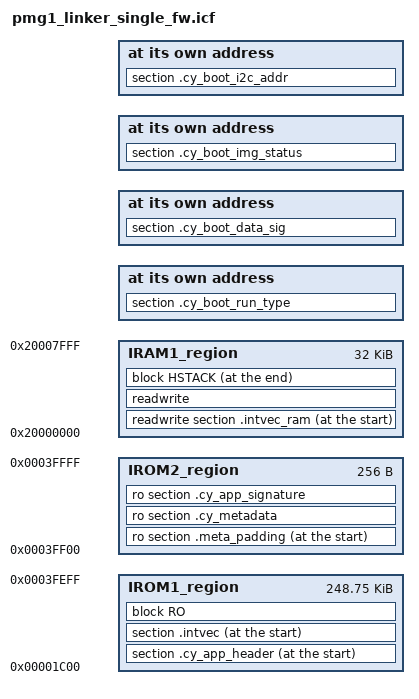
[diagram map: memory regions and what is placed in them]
/*******************************************************************************
* \file pmg1_linker_single_fw.icf
* \version 1.0.0
*
* Linker file for the IAR compiler.
*
* The main purpose of the linker script is to describe how the sections in the
* input files should be mapped into the output file, and to control the memory
* layout of the output file.
*
* \note The entry point is fixed and starts at 0x00000000. The valid application
* image should be placed there.
*
* \note The linker files included with the PDL template projects must be generic
* and handle all common use cases. Your project may not use every section
* defined in the linker files. In that case you may see warnings during the
* build process. In your project, you can simply comment out or remove the
* relevant code in the linker file.
*
********************************************************************************
* \copyright
* (c) (2024), Cypress Semiconductor Corporation (an Infineon company) or
* an affiliate of Cypress Semiconductor Corporation.
*
* SPDX-License-Identifier: Apache-2.0
*
* Licensed under the Apache License, Version 2.0 (the "License");
* you may not use this file except in compliance with the License.
* You may obtain a copy of the License at
*
*     http://www.apache.org/licenses/LICENSE-2.0
*
* Unless required by applicable law or agreed to in writing, software
* distributed under the License is distributed on an "AS IS" BASIS,
* WITHOUT WARRANTIES OR CONDITIONS OF ANY KIND, either express or implied.
* See the License for the specific language governing permissions and
* limitations under the License.
*******************************************************************************/

/*###ICF### Section handled by ICF editor, don't touch! ****/
/*-Editor annotation file-*/
/* IcfEditorFile="$TOOLKIT_DIR$\config\ide\IcfEditor\cortex_v1_4.xml" */
/*-Specials-*/
define symbol __ICFEDIT_intvec_start__ = 0x00000000;

/* The symbols below define the location and size of blocks of memory in the target.
 * Use these symbols to specify the memory regions available for allocation.
 */

/* The following symbols control RAM and flash memory allocation.
 * You can change the memory allocation by editing RAM and Flash symbols.
 */
/* RAM */
define symbol __ICFEDIT_region_IRAM1_start__         = 0x20000000;
define symbol __ICFEDIT_region_IRAM1_end__           = 0x20007FFF;
define symbol __ICFEDIT_region_IRAM2_start__         = 0x0;
define symbol __ICFEDIT_region_IRAM2_end__           = 0x0;
define symbol __ICFEDIT_region_IRAM3_start__         = 0x0;
define symbol __ICFEDIT_region_IRAM3_end__           = 0x0;
define symbol __ICFEDIT_region_ERAM1_start__         = 0x0;
define symbol __ICFEDIT_region_ERAM1_end__           = 0x0;
define symbol __ICFEDIT_region_ERAM2_start__         = 0x0;
define symbol __ICFEDIT_region_ERAM2_end__           = 0x0;
define symbol __ICFEDIT_region_ERAM3_start__         = 0x0;
define symbol __ICFEDIT_region_ERAM3_end__           = 0x0;

/* Flash */
define symbol __ICFEDIT_region_IROM_Boot_start__     = 0x00000000;
define symbol __ICFEDIT_region_IROM_Boot_end__       = 0x00001BFF;
define symbol __ICFEDIT_region_IROM_Fw_start__       = 0x00001C00;
define symbol __ICFEDIT_region_IROM_Fw_end__         = 0x0003FEFF;
define symbol __ICFEDIT_region_IROM_Fw_Meta_start__  = 0x0003FF00;
define symbol __ICFEDIT_region_IROM_Fw_Meta_end__    = 0x0003FFFF;
define symbol __ICFEDIT_region_EROM1_start__         = 0x0;
define symbol __ICFEDIT_region_EROM1_end__           = 0x0;
define symbol __ICFEDIT_region_EROM2_start__         = 0x0;
define symbol __ICFEDIT_region_EROM2_end__           = 0x0;
define symbol __ICFEDIT_region_EROM3_start__         = 0x0;
define symbol __ICFEDIT_region_EROM3_end__           = 0x0;

/*-Sizes-*/
if (!isdefinedsymbol(__STACK_SIZE)) {
define symbol __ICFEDIT_size_cstack__ = 0x0400;
} else {
define symbol __ICFEDIT_size_cstack__ = __STACK_SIZE;
}
define symbol __ICFEDIT_size_proc_stack__ = 0x0;

/* Defines the minimum heap size. The actual heap size will be expanded to the end of the stack region */
if (!isdefinedsymbol(__HEAP_SIZE)) {
define symbol __ICFEDIT_size_heap__ = 0x0080;
} else {
define symbol __ICFEDIT_size_heap__ = __HEAP_SIZE;
}
/**** End of ICF editor section. ###ICF###*/


define memory mem with size = 4G;
define symbol use_IROM1 = (__ICFEDIT_region_IROM_Fw_start__ != 0x0 || __ICFEDIT_region_IROM_Fw_end__ != 0x0);
define symbol use_IROM2 = (__ICFEDIT_region_IROM_Fw_Meta_start__ != 0x0 || __ICFEDIT_region_IROM_Fw_Meta_end__ != 0x0);
define symbol use_IRAM1 = (__ICFEDIT_region_IRAM1_start__ != 0x0 || __ICFEDIT_region_IRAM1_end__ != 0x0);

define region IROM1_region = mem:[from __ICFEDIT_region_IROM_Fw_start__ to __ICFEDIT_region_IROM_Fw_end__];
define region IROM2_region = mem:[from __ICFEDIT_region_IROM_Fw_Meta_start__ to __ICFEDIT_region_IROM_Fw_Meta_end__];
define region IRAM1_region = mem:[from __ICFEDIT_region_IRAM1_start__ to __ICFEDIT_region_IRAM1_end__];

define block CSTACK     with alignment = 8, size = __ICFEDIT_size_cstack__     { };
define block PROC_STACK with alignment = 8, size = __ICFEDIT_size_proc_stack__ { };
define block HEAP       with expanding size, alignment = 8, minimum size = __ICFEDIT_size_heap__ { };
define block HSTACK {block HEAP, block PROC_STACK, last block CSTACK};
define block RO     {readonly};

/*-Initializations-*/
initialize by copy { readwrite };
do not initialize  { section .noinit, section .intvec_ram };

/*-Placement-*/

/* Flash - Application Firmware section */
".cy_app_header" : place at start of IROM1_region  { section .cy_app_header };
place at start of                    IROM1_region  { section .intvec };
place at address mem : start(IROM1_region) + 0xC0  { section .customer_region };
place at address mem : start(IROM1_region) + 0xE0  { section .cy_base_version, section .cy_app_version, section .cy_dev_siliconid, section .cy_fw_reserved};
place in                             IROM1_region  { block RO };

/* Metadata section */
".meta_padding"     : place at start of  IROM2_region  {ro section .meta_padding };
".cy_metadata"      : place in           IROM2_region  {ro section .cy_metadata};
".cy_app_signature" : place in           IROM2_region  {ro section .cy_app_signature};

/* RAM */
place at start of IRAM1_region  { readwrite section .intvec_ram};
place at address mem: start(IRAM1_region) + 0xC0  { section .cy_boot_run_type};
place at address mem: start(IRAM1_region) + 0xC4  { section .cy_boot_data_sig};
place at address mem: start(IRAM1_region) + 0xC8  { section .cy_boot_img_status};
place at address mem: start(IRAM1_region) + 0xCC  { section .cy_boot_i2c_addr};
place in          IRAM1_region  { readwrite };
place at end   of IRAM1_region  { block HSTACK };

/* These sections are used for additional metadata (silicon revision, Silicon/JTAG ID, etc.) storage. */
".cyflashprotect" : place at address mem : 0x90400000 { readonly section .cyflashprotect };
".cymeta"         : place at address mem : 0x90500000 { readonly section .cymeta };
".cychipprotect"  : place at address mem : 0x90600000 { readonly section .cychipprotect };


keep {  section .cy_app_header,
        section .vectors,
        section .customer_region,
        section .cy_base_version,
        section .cy_app_version,
        section .cy_dev_siliconid,
        section .cy_fw_reserved,
        section .cy_boot_run_type,
        section .cy_boot_data_sig,
        section .cy_boot_img_status,
        section .cy_boot_i2c_addr,
        section .meta_padding,
        section .cy_metadata,
        section .cy_app_signature,
        section .cyflashprotect,
        section .cymeta,
        section .cychipprotect,
         };


/* The following symbols used by the cymcuelftool. */
/* Flash */
define exported symbol __cy_memory_0_start    = start(IROM1_region);
define exported symbol __cy_memory_0_length   = size(IROM1_region);
define exported symbol __cy_memory_0_row_size = 0x100;

define exported symbol __cy_memory_1_start    = start(IROM2_region);
define exported symbol __cy_memory_1_length   = size(IROM2_region);
define exported symbol __cy_memory_1_row_size = 0x100;

/*******************************************************************************
* The following symbols used by the cymcuelftool and application firmware
*******************************************************************************/
/* The Product ID, used by CyMCUElfTool to generate a updating file */
define exported symbol __cy_product_id = 0x01020304;

/* The checksum type used by CyMCUElfTool to generate a updating file */
define exported symbol __cy_checksum_type = 0x00;

/*
* The size of the application signature.
* E.g. 4 for CRC-32,
*     32 for SHA256,
*    256 for RSA 2048.
*/
define exported symbol __cy_boot_signature_size = 4;

/* Application specific sets an app Id */
define exported symbol __cy_app_id = 1;

/* Application specific */
/* CyMCUElfTool uses these ELF symbols to generate an application signature */
/* _flash_datasize is calculated here to get the complete flash size used. */
define exported symbol __cy_app_verify_start  = start(IROM1_region);
define exported symbol __cy_app_verify_length = size(IROM1_region);

/* EOF */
